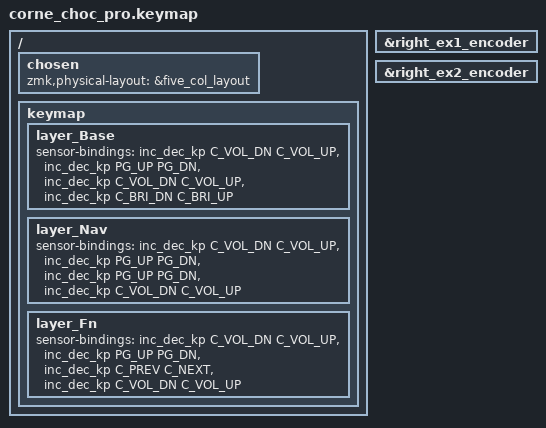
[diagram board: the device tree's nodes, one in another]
/*
 * Corne Choc Pro — thin wrapper around base.keymap.
 *
 * Physical layout: 5-column, encoders on right half only.
 *
 * The 5-col transform has 40 key positions:
 *   Row 0:  5 left  + (encL encR) + 5 right  = 12
 *   Row 1:  5 left  + (encL encR) + 5 right  = 12
 *   Row 2:  5 left  + 5 right                = 10
 *   Thumb:  3 left  + 3 right                =  6
 *
 * Encoder positions 5,17 (left) → &none (no left encoders).
 * Encoder positions 6,18 (right) → encoder press buttons.
 * Encoder rotation is handled by sensor-bindings (right_ex1 & right_ex2).
 *
 * Architecture follows github.com/urob/zmk-config.
 */

#define CONFIG_WIRELESS
#define CONFIG_HAS_RGB_UNDERGLOW

/* ── Adapt the 34-key base layout to the 40-position 5-col grid ──────────
 *
 * base.keymap calls ZMK_BASE_LAYER(name, LT, RT, LM, RM, LB, RB, LH, RH)
 * where LT/RT/LM/RM/LB/RB are 5 keys each and LH/RH are 3 thumbs each.
 * We splice in the encoder-area keys between left and right halves.
 * ──────────────────────────────────────────────────────────────────────── */

#define ZMK_BASE_LAYER(name, LT, RT, LM, RM, LB, RB, LH, RH)                \
    ZMK_LAYER(                                                                 \
        name,                                                                  \
        LT &none &kp C_MUTE RT                                                \
        LM &none &kp C_PP   RM                                                \
        LB                  RB                                                 \
        LH                  RH                                                 \
    )

/* ── 40-position key labels for combos & HRMs ────────────────────────── *
 * Start from the 36-key labels, then patch every position that shifts   *
 * due to the two encoder columns inserted in rows 0 and 1.             *
 *                                                                      *
 * 40-key physical matrix:                                              *
 *   Row 0:  0  1  2  3  4 │ 5  6 │  7  8  9 10 11  (enc cols 5,6)    *
 *   Row 1: 12 13 14 15 16 │17 18 │ 19 20 21 22 23  (enc cols 17,18)   *
 *   Row 2: 24 25 26 27 28 │      │ 29 30 31 32 33                     *
 *   Thumb:       34 35 36 │      │ 37 38 39                           *
 * ──────────────────────────────────────────────────────────────────── */
#include "zmk-helpers/key-labels/36.h"

/* Left-side middle row (shifted +2 by encoder cols at 5,6 in row 0) */
#undef LM0
#undef LM1
#undef LM2
#undef LM3
#undef LM4
#define LM0 16
#define LM1 15
#define LM2 14
#define LM3 13
#define LM4 12

/* Right-side top row (shifted +2 by encoder cols at 5,6) */
#undef RT0
#undef RT1
#undef RT2
#undef RT3
#undef RT4
#define RT0  7
#define RT1  8
#define RT2  9
#define RT3 10
#define RT4 11

/* Right-side middle row (shifted +2 by encoder cols at 17,18) */
#undef RM0
#undef RM1
#undef RM2
#undef RM3
#undef RM4
#define RM0 19
#define RM1 20
#define RM2 21
#define RM3 22
#define RM4 23

/* Bottom row: left stays, right shifts +4 total (rows 0–1 added 4 positions) */
#undef LB4
#undef LB3
#undef LB2
#undef LB1
#undef LB0
#define LB4 24
#define LB3 25
#define LB2 26
#define LB1 27
#define LB0 28

#undef RB0
#undef RB1
#undef RB2
#undef RB3
#undef RB4
#define RB0 29
#define RB1 30
#define RB2 31
#define RB3 32
#define RB4 33

/* Thumbs: shifted +4 total */
#undef LH2
#undef LH1
#undef LH0
#define LH2 34
#define LH1 35
#define LH0 36

#undef RH0
#undef RH1
#undef RH2
#define RH0 37
#define RH1 38
#define RH2 39

/* Override KEYS_L / KEYS_R / THUMBS for this board's HRM config.
 * base.keymap uses #ifndef guards, so these take precedence. */
#define KEYS_L LT0 LT1 LT2 LT3 LT4 LM0 LM1 LM2 LM3 LM4 LB0 LB1 LB2 LB3 LB4
#define KEYS_R RT0 RT1 RT2 RT3 RT4 RM0 RM1 RM2 RM3 RM4 RB0 RB1 RB2 RB3 RB4
#define THUMBS LH0 LH1 LH2 RH0 RH1 RH2

/* Pull in the shared base keymap. */
#include "base.keymap"

/* ── Physical layout selection ─────────────────────────────────────────── */

/ {
    chosen {
        zmk,physical-layout = &five_col_layout;
    };
};

/* ── Encoders ──────────────────────────────────────────────────────────── */

&right_ex1_encoder {
    status = "okay";
};

&right_ex2_encoder {
    status = "okay";
};

/* Overlay sensor-bindings onto layers generated by base.keymap.
 * Sensor order: left_ex1, left_ex2, right_ex1, right_ex2.
 * Left placeholders required even though not installed. */

/ {
    keymap {
        layer_Base {
            sensor-bindings =
                <&inc_dec_kp C_VOL_DN C_VOL_UP>,
                <&inc_dec_kp PG_UP PG_DN>,
                <&inc_dec_kp C_VOL_DN C_VOL_UP>,    /* right_ex1: volume */
                <&inc_dec_kp C_BRI_DN C_BRI_UP>     /* right_ex2: brightness */
            ;
        };
        layer_Nav {
            sensor-bindings =
                <&inc_dec_kp C_VOL_DN C_VOL_UP>,
                <&inc_dec_kp PG_UP PG_DN>,
                <&inc_dec_kp PG_UP PG_DN>,          /* right_ex1: page up/down */
                <&inc_dec_kp C_VOL_DN C_VOL_UP>     /* right_ex2: volume */
            ;
        };
        layer_Fn {
            sensor-bindings =
                <&inc_dec_kp C_VOL_DN C_VOL_UP>,
                <&inc_dec_kp PG_UP PG_DN>,
                <&inc_dec_kp C_PREV C_NEXT>,        /* right_ex1: prev/next track */
                <&inc_dec_kp C_VOL_DN C_VOL_UP>     /* right_ex2: volume */
            ;
        };
    };
};

/* vim: set ft=c tw=146: */
